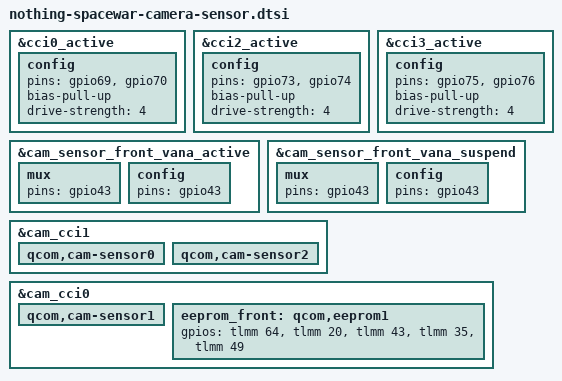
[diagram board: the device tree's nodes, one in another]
// nothing-spacewar-camera-sensor.dtsi
// Nothing Phone (1) "spacewar"

#include <dt-bindings/clock/qcom,camcc-yupik.h>

&cci0_active {
	config {
		pins = "gpio69", "gpio70";
		bias-pull-up;
		drive-strength = <4>; /* 4 MA */
	};
};

&cci2_active {
	config {
		pins = "gpio73", "gpio74";
		bias-pull-up;
		drive-strength = <4>; /* 4 MA */
	};
};

&cci3_active {
	config {
		pins = "gpio75", "gpio76";
		bias-pull-up;
		drive-strength = <4>; /* 4 MA */
	};
};

/*
 * abra-camera-sensor.dtsi's "front vana" pinctrl node points at
 * gpio40, but the bench-verified regulator map (vreg_camf_vana_2p8) shows
 * the real front-camera 2.8V VANA line is gpio43 - the same pin already
 * wired up in qcom,cam-sensor1's own pinctrl.
 * Repointing this node makes the label match the actual hardware function;
 * gpio40 is left alone since nothing else on this board claims it.
 */
&cam_sensor_front_vana_active {
	mux {
		pins = "gpio43";
	};

	config {
		pins = "gpio43";
	};
};

&cam_sensor_front_vana_suspend {
	mux {
		pins = "gpio43";
	};

	config {
		pins = "gpio43";
	};
};

/* Rear wide - Sony IMX766, C-PHY, OIS, I2C 0x10 */
&cam_cci1 {
	qcom,cam-sensor0 {
		status = "ok";
	};
};

/* Rear ultrawide - Samsung S5KJN1, D-PHY, I2C 0x2d */
&cam_cci1 {
	qcom,cam-sensor2 {
		status = "ok";
	};
};

/* Front - Sony IMX471, D-PHY, I2C 0x1a */
&cam_cci0 {
	qcom,cam-sensor1 {
		status = "ok";
	};
};

&cam_cci0 {
	eeprom_front: qcom,eeprom1 {
		gpios = <&tlmm 64 0>,
			<&tlmm 20 0>,
			<&tlmm 43 0>,
			<&tlmm 35 0>,
			<&tlmm 49 0>;
	};
};
